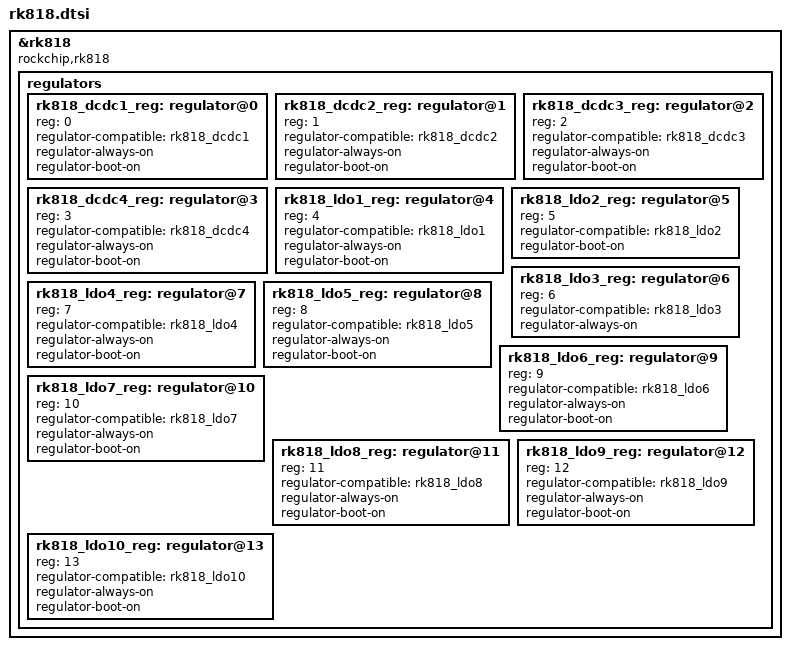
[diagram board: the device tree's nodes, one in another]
// SPDX-License-Identifier: (GPL-2.0+ OR MIT)

&rk818 {
	compatible = "rockchip,rk818";
	
	regulators {
		#address-cells = <1>;
		#size-cells = <0>;	

		rk818_dcdc1_reg: regulator@0 {
			reg = <0>;
			regulator-compatible = "rk818_dcdc1";
			regulator-always-on;
			regulator-boot-on;
		};

		rk818_dcdc2_reg: regulator@1 {
			reg = <1>;
			regulator-compatible = "rk818_dcdc2";
			regulator-always-on;
			regulator-boot-on;		
		};

		rk818_dcdc3_reg: regulator@2 {
			reg = <2>;
			regulator-compatible = "rk818_dcdc3";
			regulator-always-on;
			regulator-boot-on;
		};

		rk818_dcdc4_reg: regulator@3 {
			reg = <3>;
			regulator-compatible = "rk818_dcdc4";
			regulator-always-on;
			regulator-boot-on;	
		};

		rk818_ldo1_reg: regulator@4 {
			reg = <4>;
			regulator-compatible = "rk818_ldo1";
			regulator-always-on;
			regulator-boot-on;
		};

		rk818_ldo2_reg: regulator@5 {
			reg = <5>;
			regulator-compatible = "rk818_ldo2";
		//	regulator-always-on;
			regulator-boot-on;
		};

		rk818_ldo3_reg: regulator@6 {
			reg = <6>;
			regulator-compatible = "rk818_ldo3";
			regulator-always-on;
			/*regulator-boot-on;*/
		};

		rk818_ldo4_reg: regulator@7{
			reg = <7>;
			regulator-compatible = "rk818_ldo4";
			regulator-always-on;
			regulator-boot-on;	
		};

		rk818_ldo5_reg: regulator@8{
			reg = <8>;
			regulator-compatible = "rk818_ldo5";
			regulator-always-on;
			regulator-boot-on;	
		};

		rk818_ldo6_reg: regulator@9{
			reg = <9>;
			regulator-compatible = "rk818_ldo6";
			regulator-always-on;
			regulator-boot-on;
		};

		rk818_ldo7_reg: regulator@10 {
			reg = <10>;
			regulator-compatible = "rk818_ldo7";
			regulator-always-on;
			regulator-boot-on;
		};

		rk818_ldo8_reg: regulator@11{
			reg = <11>;
			regulator-compatible = "rk818_ldo8";
			regulator-always-on;
			regulator-boot-on;
		};
		
			rk818_ldo9_reg: regulator@12{
			reg = <12>;
			regulator-compatible = "rk818_ldo9";
			regulator-always-on;
			regulator-boot-on;	
		};
		
			rk818_ldo10_reg: regulator@13{
			reg = <13>;
			regulator-compatible = "rk818_ldo10";
			regulator-always-on;
			regulator-boot-on;
		};

	};
};
